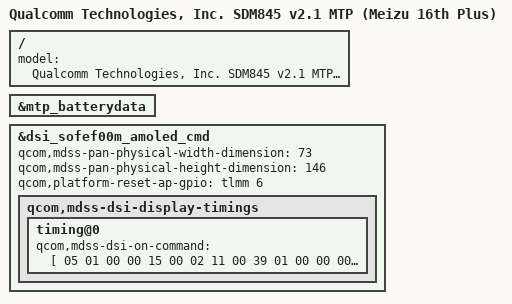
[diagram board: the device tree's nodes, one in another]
/*
 * Copyright (C) 2023 transaero21 <transaero21@elseboot.ru>
 *
 * SPDX-License-Identifier: GPL-2.0
 */

/dts-v1/;
/plugin/;

#include "sdm845-v2.1-mtp-overlay.dtsi"

/ {
	model = "Qualcomm Technologies, Inc. SDM845 v2.1 MTP (Meizu 16th Plus)";
};

&mtp_batterydata {
	#include "batterydata-meizu-m1892-3600mah.dtsi"
};

&dsi_sofef00m_amoled_cmd {
	qcom,mdss-pan-physical-width-dimension = <73>;
	qcom,mdss-pan-physical-height-dimension = <146>;
	qcom,platform-reset-ap-gpio = <&tlmm 6 0>;

	qcom,mdss-dsi-display-timings {
		timing@0 {
			qcom,mdss-dsi-on-command = [
				05 01 00 00 15 00 02 11 00 39 01 00
				00 00 00 03 F0 5A 5A 39 01 00 00 00
				00 03 FC 5A 5A 39 01 00 00 00 00 02
				B0 03 39 01 00 00 00 00 02 D2 9E 39
				01 00 00 00 00 03 F0 A5 A5 39 01 00
				00 00 00 03 FC A5 A5 39 01 00 00 00
				00 03 F0 5A 5A 15 01 00 00 00 00 02
				35 00 39 01 00 00 00 00 03 F0 A5 A5
				39 01 00 00 00 00 05 2B 00 00 08 6F
				39 01 00 00 00 00 03 F0 5A 5A 39 01
				00 00 00 00 02 B0 01 39 01 00 00 00
				00 02 BB 03 39 01 00 00 00 00 02 B0
				03 39 01 00 00 00 00 04 EF 33 31 14
				39 01 00 00 00 00 03 F0 A5 A5 15 01
				00 00 00 00 02 53 28 39 01 00 00 00
				00 03 51 00 00 15 01 00 00 00 00 02
				55 00 39 01 00 00 00 00 03 F0 5A 5A
				39 01 00 00 00 00 03 F0 5A 5A 15 01
				00 00 00 00 02 B0 05 15 01 00 00 00
				00 02 B1 03 39 01 00 00 00 00 03 F0
				A5 A5 15 01 00 00 00 00 02 B0 02 39
				01 00 00 00 00 40 E2 B3 0C 04 39 CE
				13 07 04 AF 44 E6 CD C9 11 C2 EA E6
				18 FF FF FF F1 10 07 00 C0 00 07 05
				B5 00 D7 C0 FF 16 C4 E7 E4 0F FF FF
				FF BD 02 00 0C D6 01 06 04 A5 06 EE
				C9 C8 0A DF D1 E7 06 FF FE FE 39 01
				00 00 00 00 03 F0 A5 A5 39 01 00 00
				00 00 03 F0 5A 5A 15 01 00 00 00 00
				02 B0 01 15 01 00 00 00 00 02 E2 01
				39 01 00 00 00 00 03 F0 A5 A5 39 01
				00 00 00 00 03 F0 5A 5A 15 01 00 00
				00 00 02 B0 02 39 01 00 00 00 00 05
				D5 02 00 14 14 39 01 00 00 6E 00 03
				F0 A5 A5 05 01 00 00 00 00 02 29 00
			];
		};
	};
};
